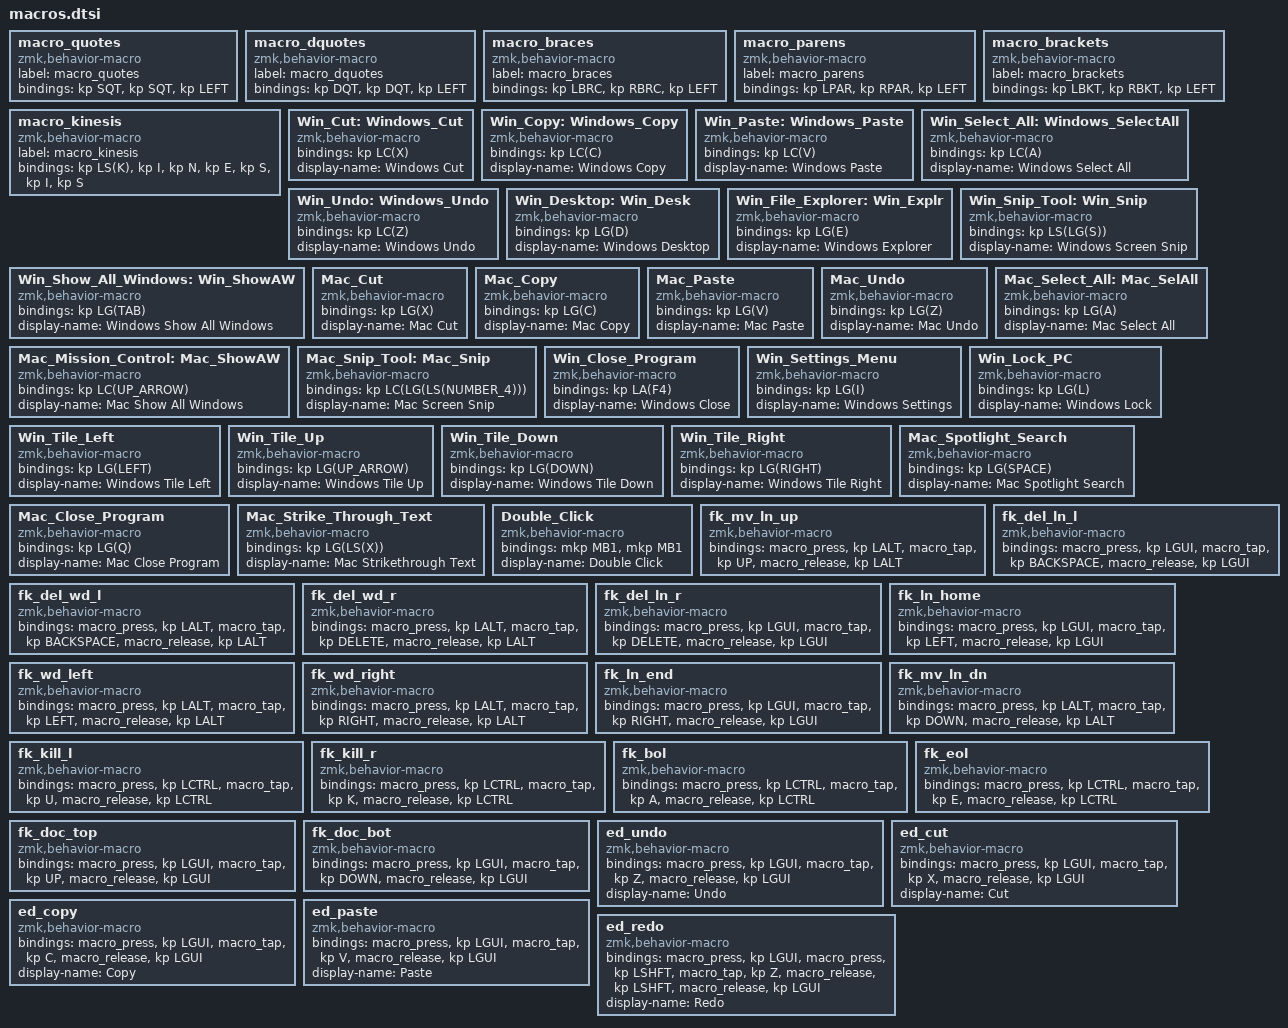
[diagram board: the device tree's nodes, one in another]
  macro_quotes: macro_quotes {
    compatible = "zmk,behavior-macro";
    label = "macro_quotes";
    #binding-cells = <0>;
    bindings = <&kp SQT>, <&kp SQT>, <&kp LEFT>;
  };
  macro_dquotes: macro_dquotes {
    compatible = "zmk,behavior-macro";
    label = "macro_dquotes";
    #binding-cells = <0>;
    bindings = <&kp DQT>, <&kp DQT>, <&kp LEFT>;
  };
  macro_braces: macro_braces {
    compatible = "zmk,behavior-macro";
    label = "macro_braces";
    #binding-cells = <0>;
    bindings = <&kp LBRC>, <&kp RBRC>, <&kp LEFT>;
  };
  macro_parens: macro_parens {
    compatible = "zmk,behavior-macro";
    label = "macro_parens";
    #binding-cells = <0>;
    bindings = <&kp LPAR>, <&kp RPAR>, <&kp LEFT>;
  };
  macro_brackets: macro_brackets {
    compatible = "zmk,behavior-macro";
    label = "macro_brackets";
    #binding-cells = <0>;
    bindings = <&kp LBKT>, <&kp RBKT>, <&kp LEFT>;
  };
  macro_kinesis: macro_kinesis {
    compatible = "zmk,behavior-macro";
    label = "macro_kinesis";
    #binding-cells = <0>;
    bindings = <&kp LS(K)>, <&kp I>, <&kp N>, <&kp E>, <&kp S>, <&kp I>, <&kp S>;
  };
  Win_Cut: Windows_Cut {
    compatible = "zmk,behavior-macro";
    #binding-cells = <0>;
    bindings = <&kp LC(X)>;
    display-name = "Windows Cut";
  };

  Win_Copy: Windows_Copy {
    compatible = "zmk,behavior-macro";
    #binding-cells = <0>;
    bindings = <&kp LC(C)>;
    display-name = "Windows Copy";
  };

  Win_Paste: Windows_Paste {
    compatible = "zmk,behavior-macro";
    #binding-cells = <0>;
    bindings = <&kp LC(V)>;
    display-name = "Windows Paste";
  };

  Win_Select_All: Windows_SelectAll {
      compatible = "zmk,behavior-macro";
      #binding-cells = <0>;
      bindings = <&kp LC(A)>;
      display-name = "Windows Select All";
  };

  Win_Undo: Windows_Undo {
    compatible = "zmk,behavior-macro";
    #binding-cells = <0>;
    bindings = <&kp LC(Z)>;
    display-name = "Windows Undo";
  };

  Win_Desktop: Win_Desk {
    compatible = "zmk,behavior-macro";
    #binding-cells = <0>;
    bindings = <&kp LG(D)>;
    display-name = "Windows Desktop";
  };

  Win_File_Explorer: Win_Explr {
    compatible = "zmk,behavior-macro";
    #binding-cells = <0>;
    bindings = <&kp LG(E)>;
    display-name = "Windows Explorer";
  };

  Win_Snip_Tool: Win_Snip {
    compatible = "zmk,behavior-macro";
    #binding-cells = <0>;
    bindings = <&kp LS(LG(S))>;
    display-name = "Windows Screen Snip";
  };

  Win_Show_All_Windows: Win_ShowAW {
    compatible = "zmk,behavior-macro";
    #binding-cells = <0>;
    bindings = <&kp LG(TAB)>;
    display-name = "Windows Show All Windows";
  };

  Mac_Cut: Mac_Cut {
    compatible = "zmk,behavior-macro";
    #binding-cells = <0>;
    bindings = <&kp LG(X)>;
    display-name = "Mac Cut";
  };

  Mac_Copy: Mac_Copy {
    compatible = "zmk,behavior-macro";
    #binding-cells = <0>;
    bindings = <&kp LG(C)>;
    display-name = "Mac Copy";
  };

  Mac_Paste: Mac_Paste {
    compatible = "zmk,behavior-macro";
    #binding-cells = <0>;
    bindings = <&kp LG(V)>;
    display-name = "Mac Paste";
  };

  Mac_Undo: Mac_Undo {
    compatible = "zmk,behavior-macro";
    #binding-cells = <0>;
    bindings = <&kp LG(Z)>;
    display-name = "Mac Undo";
  };

  Mac_Select_All: Mac_SelAll {
    compatible = "zmk,behavior-macro";
    #binding-cells = <0>;
    bindings = <&kp LG(A)>;
    display-name = "Mac Select All";
  };

  Mac_Mission_Control: Mac_ShowAW {
    compatible = "zmk,behavior-macro";
    #binding-cells = <0>;
    bindings = <&kp LC(UP_ARROW)>;
    display-name = "Mac Show All Windows";
  };

  Mac_Snip_Tool: Mac_Snip {
    compatible = "zmk,behavior-macro";
    #binding-cells = <0>;
    bindings = <&kp LC(LG(LS(NUMBER_4)))>;
    display-name = "Mac Screen Snip";
  };

  Win_Close_Program: Win_Close_Program {
    compatible = "zmk,behavior-macro";
    #binding-cells = <0>;
    bindings = <&kp LA(F4)>;
    display-name = "Windows Close";
  };

  Win_Settings_Menu: Win_Settings_Menu {
    compatible = "zmk,behavior-macro";
    #binding-cells = <0>;
    bindings = <&kp LG(I)>;
    display-name = "Windows Settings";
  };

  Win_Lock_PC: Win_Lock_PC {
    compatible = "zmk,behavior-macro";
    #binding-cells = <0>;
    bindings = <&kp LG(L)>;
    display-name = "Windows Lock";
  };

  Win_Tile_Left: Win_Tile_Left {
    compatible = "zmk,behavior-macro";
    #binding-cells = <0>;
    bindings = <&kp LG(LEFT)>;
    display-name = "Windows Tile Left";
  };

  Win_Tile_Up: Win_Tile_Up {
    compatible = "zmk,behavior-macro";
    #binding-cells = <0>;
    bindings = <&kp LG(UP_ARROW)>;
    display-name = "Windows Tile Up";
  };

  Win_Tile_Down: Win_Tile_Down {
    compatible = "zmk,behavior-macro";
    #binding-cells = <0>;
    bindings = <&kp LG(DOWN)>;
    display-name = "Windows Tile Down";
  };

  Win_Tile_Right: Win_Tile_Right {
    compatible = "zmk,behavior-macro";
    #binding-cells = <0>;
    bindings = <&kp LG(RIGHT)>;
    display-name = "Windows Tile Right";
  };

  Mac_Spotlight_Search: Mac_Spotlight_Search {
    compatible = "zmk,behavior-macro";
    #binding-cells = <0>;
    bindings = <&kp LG(SPACE)>;
    display-name = "Mac Spotlight Search";
  };

  Mac_Close_Program: Mac_Close_Program {
    compatible = "zmk,behavior-macro";
    #binding-cells = <0>;
    bindings = <&kp LG(Q)>;
    display-name = "Mac Close Program";
  };

  Mac_Strike_Through_Text: Mac_Strike_Through_Text {
    compatible = "zmk,behavior-macro";
    #binding-cells = <0>;
    bindings = <&kp LG(LS(X))>;
    display-name = "Mac Strikethrough Text";
  };

  Double_Click: Double_Click {
    compatible = "zmk,behavior-macro";
    #binding-cells = <0>;
    bindings = <&mkp MB1 &mkp MB1>;
    display-name = "Double Click";
  };

  /* Flykey layer macros — explicit modifier ordering.
   * Using &macro_press/&macro_tap/&macro_release ensures the modifier is set
   * in its own HID report BEFORE the key, avoiding macOS interpreting the
   * implicit-modifier combined report as a spurious standalone modifier tap. */
  fk_mv_ln_up: fk_mv_ln_up {
    compatible = "zmk,behavior-macro";
    #binding-cells = <0>;
    bindings = <&macro_press &kp LALT>, <&macro_tap &kp UP>, <&macro_release &kp LALT>;
  };
  fk_del_ln_l: fk_del_ln_l {
    compatible = "zmk,behavior-macro";
    #binding-cells = <0>;
    bindings = <&macro_press &kp LGUI>, <&macro_tap &kp BACKSPACE>, <&macro_release &kp LGUI>;
  };
  fk_del_wd_l: fk_del_wd_l {
    compatible = "zmk,behavior-macro";
    #binding-cells = <0>;
    bindings = <&macro_press &kp LALT>, <&macro_tap &kp BACKSPACE>, <&macro_release &kp LALT>;
  };
  fk_del_wd_r: fk_del_wd_r {
    compatible = "zmk,behavior-macro";
    #binding-cells = <0>;
    bindings = <&macro_press &kp LALT>, <&macro_tap &kp DELETE>, <&macro_release &kp LALT>;
  };
  fk_del_ln_r: fk_del_ln_r {
    compatible = "zmk,behavior-macro";
    #binding-cells = <0>;
    bindings = <&macro_press &kp LGUI>, <&macro_tap &kp DELETE>, <&macro_release &kp LGUI>;
  };
  fk_ln_home: fk_ln_home {
    compatible = "zmk,behavior-macro";
    #binding-cells = <0>;
    bindings = <&macro_press &kp LGUI>, <&macro_tap &kp LEFT>, <&macro_release &kp LGUI>;
  };
  fk_wd_left: fk_wd_left {
    compatible = "zmk,behavior-macro";
    #binding-cells = <0>;
    bindings = <&macro_press &kp LALT>, <&macro_tap &kp LEFT>, <&macro_release &kp LALT>;
  };
  fk_wd_right: fk_wd_right {
    compatible = "zmk,behavior-macro";
    #binding-cells = <0>;
    bindings = <&macro_press &kp LALT>, <&macro_tap &kp RIGHT>, <&macro_release &kp LALT>;
  };
  fk_ln_end: fk_ln_end {
    compatible = "zmk,behavior-macro";
    #binding-cells = <0>;
    bindings = <&macro_press &kp LGUI>, <&macro_tap &kp RIGHT>, <&macro_release &kp LGUI>;
  };
  fk_mv_ln_dn: fk_mv_ln_dn {
    compatible = "zmk,behavior-macro";
    #binding-cells = <0>;
    bindings = <&macro_press &kp LALT>, <&macro_tap &kp DOWN>, <&macro_release &kp LALT>;
  };
  fk_kill_l: fk_kill_l {
    compatible = "zmk,behavior-macro";
    #binding-cells = <0>;
    bindings = <&macro_press &kp LCTRL>, <&macro_tap &kp U>, <&macro_release &kp LCTRL>;
  };
  fk_kill_r: fk_kill_r {
    compatible = "zmk,behavior-macro";
    #binding-cells = <0>;
    bindings = <&macro_press &kp LCTRL>, <&macro_tap &kp K>, <&macro_release &kp LCTRL>;
  };
  fk_bol: fk_bol {
    compatible = "zmk,behavior-macro";
    #binding-cells = <0>;
    bindings = <&macro_press &kp LCTRL>, <&macro_tap &kp A>, <&macro_release &kp LCTRL>;
  };
  fk_eol: fk_eol {
    compatible = "zmk,behavior-macro";
    #binding-cells = <0>;
    bindings = <&macro_press &kp LCTRL>, <&macro_tap &kp E>, <&macro_release &kp LCTRL>;
  };
  fk_doc_top: fk_doc_top {
    compatible = "zmk,behavior-macro";
    #binding-cells = <0>;
    bindings = <&macro_press &kp LGUI>, <&macro_tap &kp UP>, <&macro_release &kp LGUI>;
  };
  fk_doc_bot: fk_doc_bot {
    compatible = "zmk,behavior-macro";
    #binding-cells = <0>;
    bindings = <&macro_press &kp LGUI>, <&macro_tap &kp DOWN>, <&macro_release &kp LGUI>;
  };

  /* Edit layer macros — explicit modifier ordering (same pattern as flykey macros). */
  ed_undo: ed_undo {
    compatible = "zmk,behavior-macro";
    #binding-cells = <0>;
    bindings = <&macro_press &kp LGUI>, <&macro_tap &kp Z>, <&macro_release &kp LGUI>;
    display-name = "Undo";
  };
  ed_cut: ed_cut {
    compatible = "zmk,behavior-macro";
    #binding-cells = <0>;
    bindings = <&macro_press &kp LGUI>, <&macro_tap &kp X>, <&macro_release &kp LGUI>;
    display-name = "Cut";
  };
  ed_copy: ed_copy {
    compatible = "zmk,behavior-macro";
    #binding-cells = <0>;
    bindings = <&macro_press &kp LGUI>, <&macro_tap &kp C>, <&macro_release &kp LGUI>;
    display-name = "Copy";
  };
  ed_paste: ed_paste {
    compatible = "zmk,behavior-macro";
    #binding-cells = <0>;
    bindings = <&macro_press &kp LGUI>, <&macro_tap &kp V>, <&macro_release &kp LGUI>;
    display-name = "Paste";
  };
  ed_redo: ed_redo {
    compatible = "zmk,behavior-macro";
    #binding-cells = <0>;
    bindings =
      <&macro_press &kp LGUI>, <&macro_press &kp LSHFT>,
      <&macro_tap &kp Z>,
      <&macro_release &kp LSHFT>, <&macro_release &kp LGUI>;
    display-name = "Redo";
  };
